# RZN2H register map
Vendor: Renesas Electronics Corporation; Series: RZN; File version: 1.00.00
CPU: other r0p0, little endian, MPU, no FPU, VTOR, 4 interrupt priority bits, 624 interrupts
Registers are 32-bit, read-write, reset 0x0 unless marked. A register's access mark holds for its fields unless they carry their own. Offsets are from the block's base; [hi:lo] are bit positions; {n}, {i} and the like mark numbered series; 'fields as' and 'values as' point back to an identical list.

## MBXSEM — Mailbox and Semaphore
Base 0x80240000
{0x0+4i} SEM{i} (i=0..7) — Semaphore Register {i}
  [0] SEM — Semaphore bit
    0=Resource being used; 1=Resource not being used
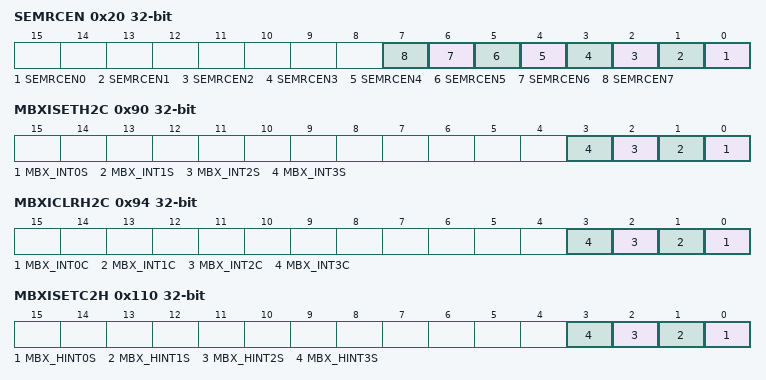
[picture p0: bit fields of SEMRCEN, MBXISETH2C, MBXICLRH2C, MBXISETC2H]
0x20 SEMRCEN — Semaphore Read Clear Enable Register
  [all] fields
    0=Disables read clear function; 1=Enables read clear function
  [n] SEMRCEN{n} (n=0..7)
{0x80+4i} MBXH2C{i} (i=0..3) ro — Host to CA55/CR52 Mailbox Register {i}
  [31:0] MBX
0x90 MBXISETH2C ro — Host to CA55/CR52 Mailbox Interrupt Set Register
  [n] MBX_INT{n}S (n=0..3) — Generates or indicates MBX_INT{n} interrupt of mailbox from external host CPU to internal Cortex-A55/Cortex-R52/CoreSight.
0x94 MBXICLRH2C — Host to CA55/CR52 Mailbox Interrupt Clear Register
  [n] MBX_INT{n}C (n=0..3) — Clears or indicates MBX_INT{n} interrupt of mailbox from external host CPU to internal Cortex-A55/Cortex-R52/CoreSight.
{0x100+4i} MBXC2H{i} (i=0..3) — CA55/CR52 to Host Mailbox Register {i}
  [31:0] MBX
0x110 MBXISETC2H — CA55/CR52 to Host Mailbox Interrupt Set Register
  [n] MBX_HINT{n}S (n=0..3) — Generates or indicates MBX_HINT{n} interrupt of mailbox from internal Cortex-A55/Cortex-R52/CoreSight to external host CPU.
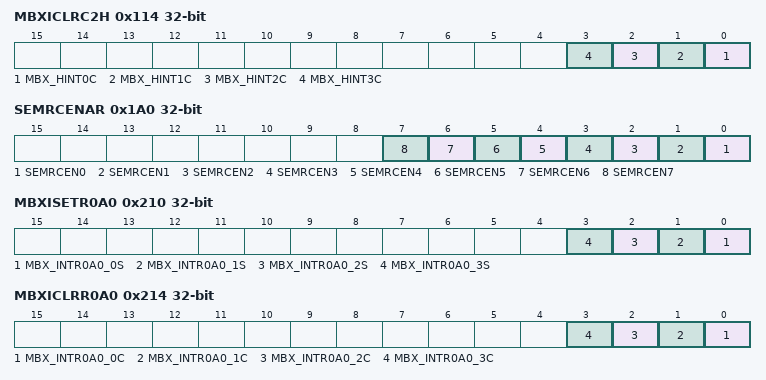
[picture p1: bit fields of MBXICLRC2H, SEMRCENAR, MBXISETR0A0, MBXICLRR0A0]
0x114 MBXICLRC2H ro — CA55/CR52 to Host Mailbox Interrupt Clear Register
  [n] MBX_HINT{n}C (n=0..3) — Clears or indicates MBX_HINT{n} interrupt of mailbox from internal Cortex-A55/Cortex-R52/CoreSight to external host CPU.
{0x180+4i} SEMAR{i} (i=0..7) — Semaphore Register {i} among Internal CPUs
  fields as SEM0
0x1A0 SEMRCENAR — Semaphore Read Clear Enable Register among Internal CPUs
  fields as SEMRCEN
{0x200+4i} MBXR0A0{i} (i=0..3) — CR52 CPU0 to CA55 Core0 Mailbox Register {i}
  [31:0] MBX
0x210 MBXISETR0A0 — CR52 CPU0 to CA55 Core0 Mailbox Interrupt Set Register
  [n] MBX_INTR0A0_{n}S (n=0..3) — Sets or indicates interrupt status flag (MBX_INTR0A{n:02}) of mailbox {n} from Cortex-R52 CPU0 to Cortex-A55 Core0.
0x214 MBXICLRR0A0 — CR52 CPU0 to CA55 Core0 Mailbox Interrupt Clear Register
  [n] MBX_INTR0A0_{n}C (n=0..3) — Clears or indicates interrupt status flag (MBX_INTR0A{n:02}) of mailbox {n} from Cortex-R52 CPU0 to Cortex-A55 Core0.
{0x280+4i} MBXR0A1{i} (i=0..3) — CR52 CPU0 to CA55 Core1 Mailbox Register {i}
  [31:0] MBX
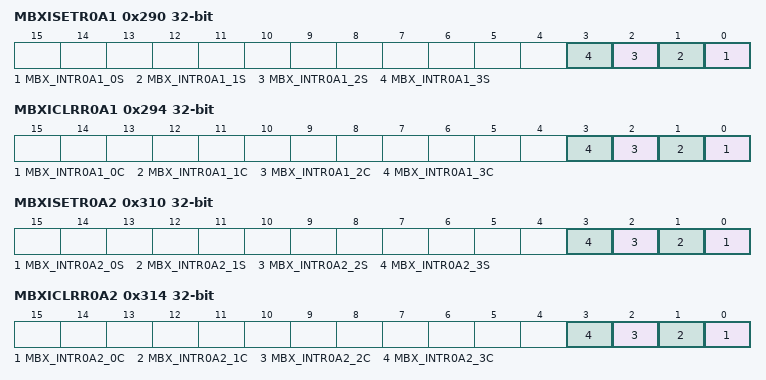
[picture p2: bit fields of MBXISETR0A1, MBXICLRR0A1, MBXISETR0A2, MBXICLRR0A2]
0x290 MBXISETR0A1 — CR52 CPU0 to CA55 Core1 Mailbox Interrupt Set Register
  [n] MBX_INTR0A1_{n}S (n=0..3) — Sets or indicates interrupt status flag (MBX_INTR0A{n+10}) of mailbox {n} from Cortex-R52 CPU0 to Cortex-A55 Core1.
0x294 MBXICLRR0A1 — CR52 CPU0 to CA55 Core1 Mailbox Interrupt Clear Register
  [n] MBX_INTR0A1_{n}C (n=0..3) — Clears or indicates interrupt status flag (MBX_INTR0A{n+10}) of mailbox {n} from Cortex-R52 CPU0 to Cortex-A55 Core1.
{0x300+4i} MBXR0A2{i} (i=0..3) — CR52 CPU0 to CA55 Core2 Mailbox Register {i}
  [31:0] MBX
0x310 MBXISETR0A2 — CR52 CPU0 to CA55 Core2 Mailbox Interrupt Set Register
  [n] MBX_INTR0A2_{n}S (n=0..3) — Sets or indicates interrupt status flag (MBX_INTR0A{n+20}) of mailbox {n} from Cortex-R52 CPU0 to Cortex-A55 Core2.
0x314 MBXICLRR0A2 — CR52 CPU0 to CA55 Core2 Mailbox Interrupt Clear Register
  [n] MBX_INTR0A2_{n}C (n=0..3) — Clears or indicates interrupt status flag (MBX_INTR0A{n+20}) of mailbox {n} from Cortex-R52 CPU0 to Cortex-A55 Core2.
{0x380+4i} MBXR0A3{i} (i=0..3) — CR52 CPU0 to CA55 Core3 Mailbox Register {i}
  [31:0] MBX
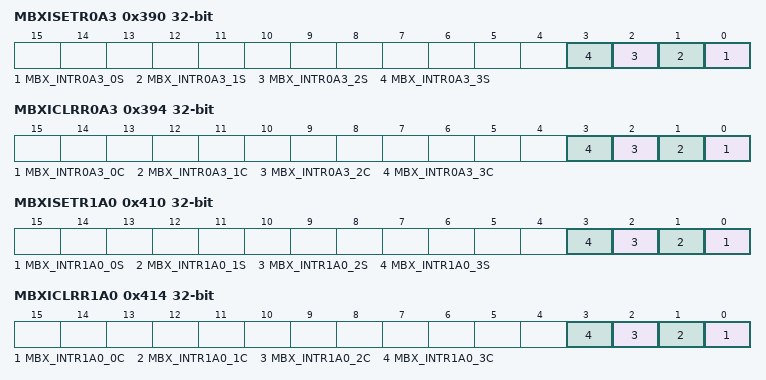
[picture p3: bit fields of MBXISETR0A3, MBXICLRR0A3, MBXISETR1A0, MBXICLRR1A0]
0x390 MBXISETR0A3 — CR52 CPU0 to CA55 Core3 Mailbox Interrupt Set Register
  [n] MBX_INTR0A3_{n}S (n=0..3) — Sets or indicates interrupt status flag (MBX_INTR0A{n+30}) of mailbox {n} from Cortex-R52 CPU0 to Cortex-A55 Core3.
0x394 MBXICLRR0A3 — CR52 CPU0 to CA55 Core3 Mailbox Interrupt Clear Register
  [n] MBX_INTR0A3_{n}C (n=0..3) — Clears or indicates interrupt status flag (MBX_INTR0A{n+30}) of mailbox {n} from Cortex-R52 CPU0 to Cortex-A55 Core3.
{0x400+4i} MBXR1A0{i} (i=0..3) — CR52 CPU1 to CA55 Core0 Mailbox Register {i}
  [31:0] MBX
0x410 MBXISETR1A0 — CR52 CPU1 to CA55 Core0 Mailbox Interrupt Set Register
  [n] MBX_INTR1A0_{n}S (n=0..3) — Sets or indicates interrupt status flag (MBX_INTR1A{n:02}) of mailbox {n} from Cortex-R52 CPU1 to Cortex-A55 Core0.
0x414 MBXICLRR1A0 — CR52 CPU1 to CA55 Core0 Mailbox Interrupt Clear Register
  [n] MBX_INTR1A0_{n}C (n=0..3) — Clears or indicates interrupt status flag (MBX_INTR1A{n:02}) of mailbox {n} from Cortex-R52 CPU1 to Cortex-A55 Core0.
{0x480+4i} MBXR1A1{i} (i=0..3) — CR52 CPU1 to CA55 Core1 Mailbox Register {i}
  [31:0] MBX
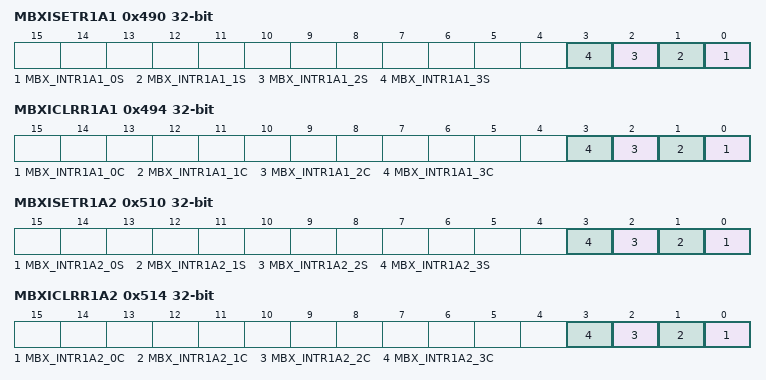
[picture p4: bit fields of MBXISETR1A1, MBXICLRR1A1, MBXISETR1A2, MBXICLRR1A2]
0x490 MBXISETR1A1 — CR52 CPU1 to CA55 Core1 Mailbox Interrupt Set Register
  [n] MBX_INTR1A1_{n}S (n=0..3) — Sets or indicates interrupt status flag (MBX_INTR1A{n+10}) of mailbox {n} from Cortex-R52 CPU1 to Cortex-A55 Core1.
0x494 MBXICLRR1A1 — CR52 CPU1 to CA55 Core1 Mailbox Interrupt Clear Register
  [n] MBX_INTR1A1_{n}C (n=0..3) — Clears or indicates interrupt status flag (MBX_INTR1A{n+10}) of mailbox {n} from Cortex-R52 CPU1 to Cortex-A55 Core1.
{0x500+4i} MBXR1A2{i} (i=0..3) — CR52 CPU1 to CA55 Core2 Mailbox Register {i}
  [31:0] MBX
0x510 MBXISETR1A2 — CR52 CPU1 to CA55 Core2 Mailbox Interrupt Set Register
  [n] MBX_INTR1A2_{n}S (n=0..3) — Sets or indicates interrupt status flag (MBX_INTR1A{n+20}) of mailbox {n} from Cortex-R52 CPU1 to Cortex-A55 Core2.
0x514 MBXICLRR1A2 — CR52 CPU1 to CA55 Core2 Mailbox Interrupt Clear Register
  [n] MBX_INTR1A2_{n}C (n=0..3) — Clears or indicates interrupt status flag (MBX_INTR1A{n+20}) of mailbox {n} from Cortex-R52 CPU1 to Cortex-A55 Core2.
{0x580+4i} MBXR1A3{i} (i=0..3) — CR52 CPU1 to CA55 Core3 Mailbox Register {i}
  [31:0] MBX
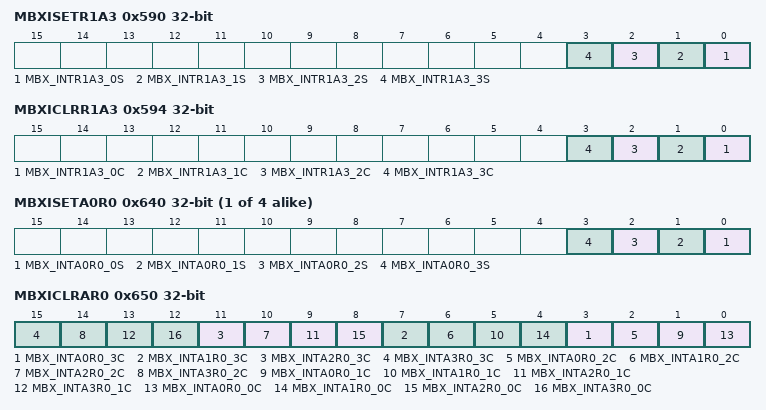
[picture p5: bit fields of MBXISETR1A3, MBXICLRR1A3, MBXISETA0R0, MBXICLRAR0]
0x590 MBXISETR1A3 — CR52 CPU1 to CA55 Core3 Mailbox Interrupt Set Register
  [n] MBX_INTR1A3_{n}S (n=0..3) — Sets or indicates interrupt status flag (MBX_INTR1A{n+30}) of mailbox {n} from Cortex-R52 CPU1 to Cortex-A55 Core3.
0x594 MBXICLRR1A3 — CR52 CPU1 to CA55 Core3 Mailbox Interrupt Clear Register
  [n] MBX_INTR1A3_{n}C (n=0..3) — Clears or indicates interrupt status flag (MBX_INTR1A{n+30}) of mailbox {n} from Cortex-R52 CPU1 to Cortex-A55 Core3.
{0x600+4i} MBXA0R0{i} (i=0..3) — CA55 Core0 to CR52 CPU0 Mailbox Register {i}
  [31:0] MBX
{0x610+4i} MBXA1R0{i} (i=0..3) — CA55 Core1 to CR52 CPU0 Mailbox Register {i}
  [31:0] MBX
{0x620+4i} MBXA2R0{i} (i=0..3) — CA55 Core2 to CR52 CPU0 Mailbox Register {i}
  [31:0] MBX
{0x630+4i} MBXA3R0{i} (i=0..3) — CA55 Core3 to CR52 CPU0 Mailbox Register {i}
  [31:0] MBX
{0x640+4i} MBXISETA{i}R0 (i=0..3) — CA55 Core{i} to CR52 CPU0 Mailbox Interrupt Set Register
  [n] MBX_INTA{i}R0_{n}S (n=0..3) — Sets or indicates interrupt status flag (MBX_INTA{i}R{n:02}) of mailbox {n} from Cortex-A55 Core{i} to Cortex-R52 CPU0.
0x650 MBXICLRAR0 — CA55 to CR52 CPU0 Mailbox Interrupt Clear Register
  [4n+3] MBX_INTA{n}R0_3C (n=0..3) — Clears or indicates interrupt status flag (MBX_INTA{n}R03) of mailbox 3 from Cortex-A55 Core{n} to Cortex-R52 CPU0.
  [4n+2] MBX_INTA{n}R0_2C (n=0..3) — Clears or indicates interrupt status flag (MBX_INTA{n}R02) of mailbox 2 from Cortex-A55 Core{n} to Cortex-R52 CPU0.
  [4n+1] MBX_INTA{n}R0_1C (n=0..3) — Clears or indicates interrupt status flag (MBX_INTA{n}R01) of mailbox 1 from Cortex-A55 Core{n} to Cortex-R52 CPU0.
  [4n] MBX_INTA{n}R0_0C (n=0..3) — Clears or indicates interrupt status flag (MBX_INTA{n}R00) of mailbox 0 from Cortex-A55 Core{n} to Cortex-R52 CPU0.
{0x680+4i} MBXA0R1{i} (i=0..3) — CA55 Core0 to CR52 CPU1 Mailbox Register {i}
  [31:0] MBX
{0x690+4i} MBXA1R1{i} (i=0..3) — CA55 Core1 to CR52 CPU1 Mailbox Register {i}
  [31:0] MBX
{0x6A0+4i} MBXA2R1{i} (i=0..3) — CA55 Core2 to CR52 CPU1 Mailbox Register {i}
  [31:0] MBX
{0x6B0+4i} MBXA3R1{i} (i=0..3) — CA55 Core3 to CR52 CPU1 Mailbox Register {i}
  [31:0] MBX
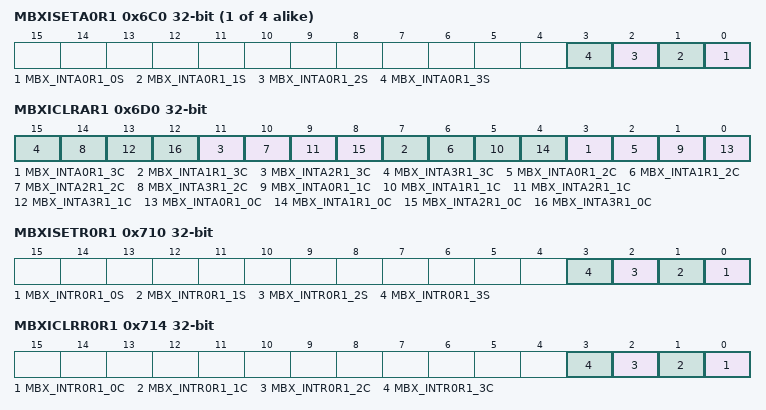
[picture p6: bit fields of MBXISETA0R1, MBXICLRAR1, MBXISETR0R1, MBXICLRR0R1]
{0x6C0+4i} MBXISETA{i}R1 (i=0..3) — CA55 Core{i} to CR52 CPU1 Mailbox Interrupt Set Register
  [n] MBX_INTA{i}R1_{n}S (n=0..3) — Sets or indicates interrupt status flag (MBX_INTA{i}R{n+10}) of mailbox {n} from Cortex-A55 Core{i} to Cortex-R52 CPU1.
0x6D0 MBXICLRAR1 — CA55 to CR52 CPU1 Mailbox Interrupt Clear Register
  [4n+3] MBX_INTA{n}R1_3C (n=0..3) — Clears or indicates interrupt status flag (MBX_INTA{n}R13) of mailbox 3 from Cortex-A55 Core{n} to Cortex-R52 CPU1.
  [4n+2] MBX_INTA{n}R1_2C (n=0..3) — Clears or indicates interrupt status flag (MBX_INTA{n}R12) of mailbox 2 from Cortex-A55 Core{n} to Cortex-R52 CPU1.
  [4n+1] MBX_INTA{n}R1_1C (n=0..3) — Clears or indicates interrupt status flag (MBX_INTA{n}R11) of mailbox 1 from Cortex-A55 Core{n} to Cortex-R52 CPU1.
  [4n] MBX_INTA{n}R1_0C (n=0..3) — Clears or indicates interrupt status flag (MBX_INTA{n}R10) of mailbox 0 from Cortex-A55 Core{n} to Cortex-R52 CPU1.
{0x700+4i} MBXR0R1{i} (i=0..3) — CR52 CPU0 to CR52 CPU1 Mailbox Register {i}
  [31:0] MBX — Mailbox from Cortex-R52 CPU0 to Cortex-R52 CPU1
0x710 MBXISETR0R1 — CR52 CPU0 to CR52 CPU1 Mailbox Interrupt Set Register
  [n] MBX_INTR0R1_{n}S (n=0..3) — Sets or indicates interrupt status flag (MBX_INTR0R{n+10}) of mailbox {n} from Cortex-R52 CPU0 to Cortex-R52 CPU1.
0x714 MBXICLRR0R1 — CR52 CPU0 to CR52 CPU1 Mailbox Interrupt Clear Register
  [n] MBX_INTR0R1_{n}C (n=0..3) — Clears or indicates interrupt status flag (MBX_INTR0R{n+10}) of mailbox {n} from Cortex-R52 CPU0 to Cortex-R52 CPU1.
{0x780+4i} MBXR1R0{i} (i=0..3) — CR52 CPU1 to CR52 CPU0 Mailbox Register {i}
  [31:0] MBX — Mailbox from Cortex-R52 CPU1 to Cortex-R52 CPU0
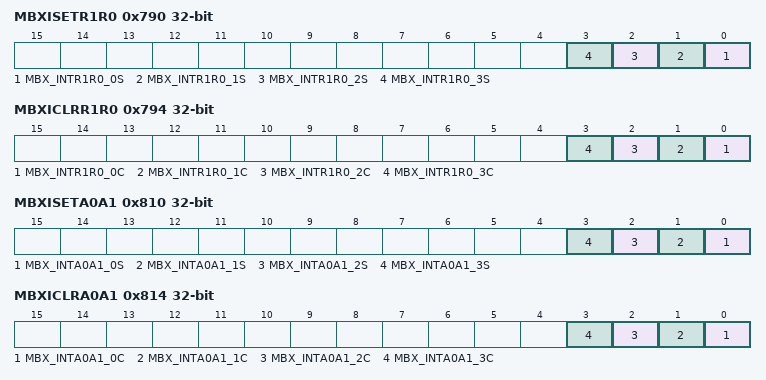
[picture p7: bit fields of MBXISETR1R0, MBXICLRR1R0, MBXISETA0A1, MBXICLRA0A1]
0x790 MBXISETR1R0 — CR52 CPU1 to CR52 CPU0 Mailbox Interrupt Set Register
  [n] MBX_INTR1R0_{n}S (n=0..3) — Sets or indicates interrupt status flag (MBX_INTR1R{n:02}) of mailbox {n} from Cortex-R52 CPU1 to Cortex-R52 CPU0.
0x794 MBXICLRR1R0 — CR52 CPU1 to CR52 CPU0 Mailbox Interrupt Clear Register
  [n] MBX_INTR1R0_{n}C (n=0..3) — Clears or indicates interrupt status flag (MBX_INTR1R{n:02}) of mailbox {n} from Cortex-R52 CPU1 to Cortex-R52 CPU0.
{0x800+4i} MBXA0A1{i} (i=0..3) — CA55 Core0 to CA55 Core1 Mailbox Register {i}
  [31:0] MBX
0x810 MBXISETA0A1 — CA55 Core0 to CA55 Core1 Mailbox Interrupt Set Register
  [n] MBX_INTA0A1_{n}S (n=0..3) — Sets or indicates interrupt status flag (MBX_INTA0A{n+10}) of mailbox {n} from Cortex-A55 Core0 to Cortex-A55 Core1.
0x814 MBXICLRA0A1 — CA55 Core0 to CA55 Core1 Mailbox Interrupt Clear Register
  [n] MBX_INTA0A1_{n}C (n=0..3) — Clears or indicates interrupt status flag (MBX_INTA0A{n+10}) of mailbox {n} from Cortex-A55 Core0 to Cortex-A55 Core1.
{0x880+4i} MBXA0A2{i} (i=0..3) — CA55 Core0 to CA55 Core2 Mailbox Register {i}
  [31:0] MBX
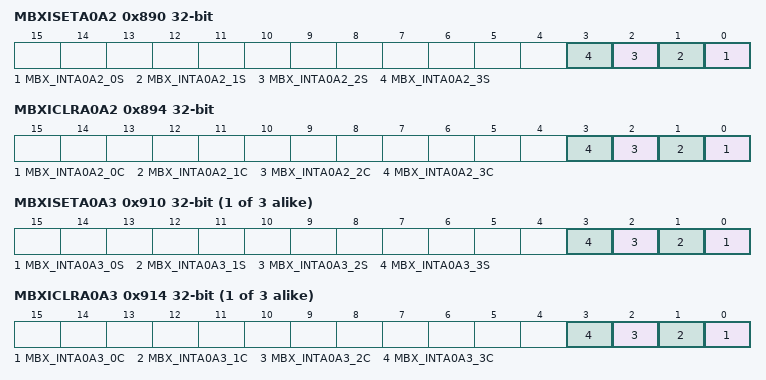
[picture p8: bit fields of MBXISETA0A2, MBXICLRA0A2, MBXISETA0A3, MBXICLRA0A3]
0x890 MBXISETA0A2 — CA55 Core0 to CA55 Core2 Mailbox Interrupt Set Register
  [n] MBX_INTA0A2_{n}S (n=0..3) — Sets or indicates interrupt status flag (MBX_INTA0A{n+20}) of mailbox {n} from Cortex-A55 Core0 to Cortex-A55 Core2.
0x894 MBXICLRA0A2 — CA55 Core0 to CA55 Core2 Mailbox Interrupt Clear Register
  [n] MBX_INTA0A2_{n}C (n=0..3) — Clears or indicates interrupt status flag (MBX_INTA0A{n+20}) of mailbox {n} from Cortex-A55 Core0 to Cortex-A55 Core2.
{0x900+4i} MBXA0A3{i} (i=0..3) — CA55 Core0 to CA55 Core3 Mailbox Register {i}
  [31:0] MBX
{0x910+0x180*i} MBXISETA{i}A3 (i=0..2) — CA55 Core{i} to CA55 Core3 Mailbox Interrupt Set Register
  [n] MBX_INTA{i}A3_{n}S (n=0..3) — Sets or indicates interrupt status flag (MBX_INTA{i}A{n+30}) of mailbox {n} from Cortex-A55 Core{i} to Cortex-A55 Core3.
{0x914+0x180*i} MBXICLRA{i}A3 (i=0..2) — CA55 Core{i} to CA55 Core3 Mailbox Interrupt Clear Register
  [n] MBX_INTA{i}A3_{n}C (n=0..3) — Clears or indicates interrupt status flag (MBX_INTA{i}A{n+30}) of mailbox {n} from Cortex-A55 Core{i} to Cortex-A55 Core3.
{0x980+4i} MBXA1A0{i} (i=0..3) — CA55 Core1 to CA55 Core0 Mailbox Register {i}
  [31:0] MBX
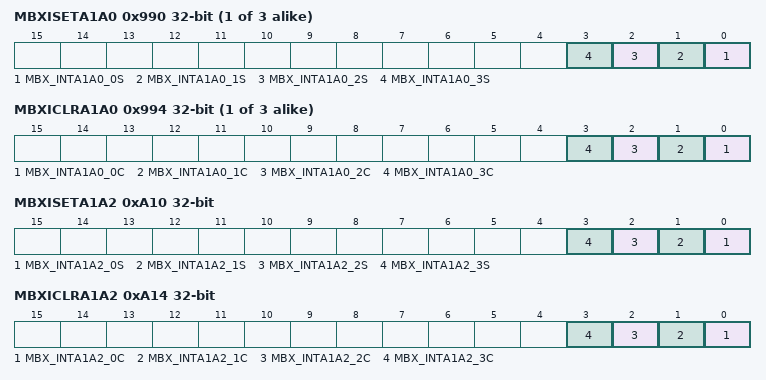
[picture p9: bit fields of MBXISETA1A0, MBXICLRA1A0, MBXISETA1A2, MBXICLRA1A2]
{0x810+0x180*i} MBXISETA{i}A0 (i=1..3) — CA55 Core{i} to CA55 Core0 Mailbox Interrupt Set Register
  [n] MBX_INTA{i}A0_{n}S (n=0..3) — Sets or indicates interrupt status flag (MBX_INTA{i}A{n:02}) of mailbox {n} from Cortex-A55 Core{i} to Cortex-A55 Core0.
{0x814+0x180*i} MBXICLRA{i}A0 (i=1..3) — CA55 Core{i} to CA55 Core0 Mailbox Interrupt Clear Register
  [n] MBX_INTA{i}A0_{n}C (n=0..3) — Clears or indicates interrupt status flag (MBX_INTA{i}A{n:02}) of mailbox {n} from Cortex-A55 Core{i} to Cortex-A55 Core0.
{0xA00+4i} MBXA1A2{i} (i=0..3) — CA55 Core1 to CA55 Core2 Mailbox Register {i}
  [31:0] MBX
0xA10 MBXISETA1A2 — CA55 Core1 to CA55 Core2 Mailbox Interrupt Set Register
  [n] MBX_INTA1A2_{n}S (n=0..3) — Sets or indicates interrupt status flag (MBX_INTA1A{n+20}) of mailbox {n} from Cortex-A55 Core1 to Cortex-A55 Core2.
0xA14 MBXICLRA1A2 — CA55 Core1 to CA55 Core2 Mailbox Interrupt Clear Register
  [n] MBX_INTA1A2_{n}C (n=0..3) — Clears or indicates interrupt status flag (MBX_INTA1A{n+20}) of mailbox {n} from Cortex-A55 Core1 to Cortex-A55 Core2.
{0xA80+4i} MBXA1A3{i} (i=0..3) — CA55 Core1 to CA55 Core3 Mailbox Register {i}
  [31:0] MBX
{0xB00+4i} MBXA2A0{i} (i=0..3) — CA55 Core2 to CA55 Core0 Mailbox Register {i}
  [31:0] MBX
{0xB80+4i} MBXA2A1{i} (i=0..3) — CA55 Core2 to CA55 Core1 Mailbox Register {i}
  [31:0] MBX
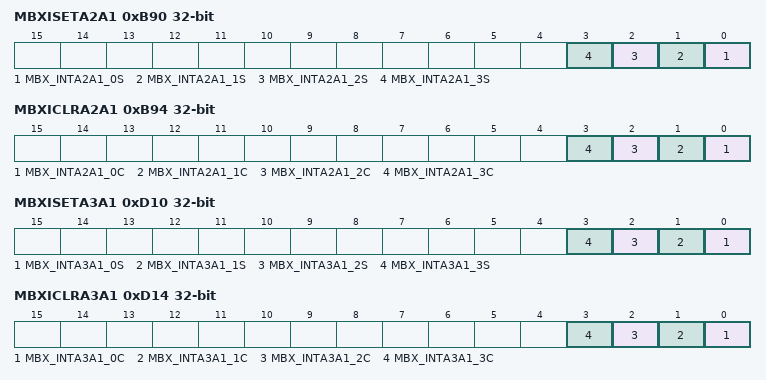
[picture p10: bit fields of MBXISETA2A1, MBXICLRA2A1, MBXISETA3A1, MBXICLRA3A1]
0xB90 MBXISETA2A1 — CA55 Core2 to CA55 Core1 Mailbox Interrupt Set Register
  [n] MBX_INTA2A1_{n}S (n=0..3) — Sets or indicates interrupt status flag (MBX_INTA2A{n+10}) of mailbox {n} from Cortex-A55 Core2 to Cortex-A55 Core1.
0xB94 MBXICLRA2A1 — CA55 Core2 to CA55 Core1 Mailbox Interrupt Clear Register
  [n] MBX_INTA2A1_{n}C (n=0..3) — Clears or indicates interrupt status flag (MBX_INTA2A{n+10}) of mailbox {n} from Cortex-A55 Core2 to Cortex-A55 Core1.
{0xC00+4i} MBXA2A3{i} (i=0..3) — CA55 Core2 to CA55 Core3 Mailbox Register {i}
  [31:0] MBX
{0xC80+4i} MBXA3A0{i} (i=0..3) — CA55 Core3 to CA55 Core0 Mailbox Register {i}
  [31:0] MBX
{0xD00+4i} MBXA3A1{i} (i=0..3) — CA55 Core3 to CA55 Core1 Mailbox Register {i}
  [31:0] MBX
0xD10 MBXISETA3A1 — CA55 Core3 to CA55 Core1 Mailbox Interrupt Set Register
  [n] MBX_INTA3A1_{n}S (n=0..3) — Sets or indicates interrupt status flag (MBX_INTA3A{n+10}) of mailbox {n} from Cortex-A55 Core3 to Cortex-A55 Core1.
0xD14 MBXICLRA3A1 — CA55 Core3 to CA55 Core1 Mailbox Interrupt Clear Register
  [n] MBX_INTA3A1_{n}C (n=0..3) — Clears or indicates interrupt status flag (MBX_INTA3A{n+10}) of mailbox {n} from Cortex-A55 Core3 to Cortex-A55 Core1.
{0xD80+4i} MBXA3A2{i} (i=0..3) — CA55 Core3 to CA55 Core2 Mailbox Register {i}
  [31:0] MBX
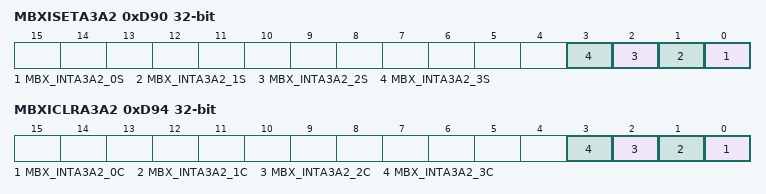
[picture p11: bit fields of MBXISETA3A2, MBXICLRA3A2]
0xD90 MBXISETA3A2 — CA55 Core3 to CA55 Core2 Mailbox Interrupt Set Register
  [n] MBX_INTA3A2_{n}S (n=0..3) — Sets or indicates interrupt status flag (MBX_INTA3A{n+20}) of mailbox {n} from Cortex-A55 Core3 to Cortex-A55 Core2.
0xD94 MBXICLRA3A2 — CA55 Core3 to CA55 Core2 Mailbox Interrupt Clear Register
  [n] MBX_INTA3A2_{n}C (n=0..3) — Clears or indicates interrupt status flag (MBX_INTA3A{n+20}) of mailbox {n} from Cortex-A55 Core3 to Cortex-A55 Core2.
